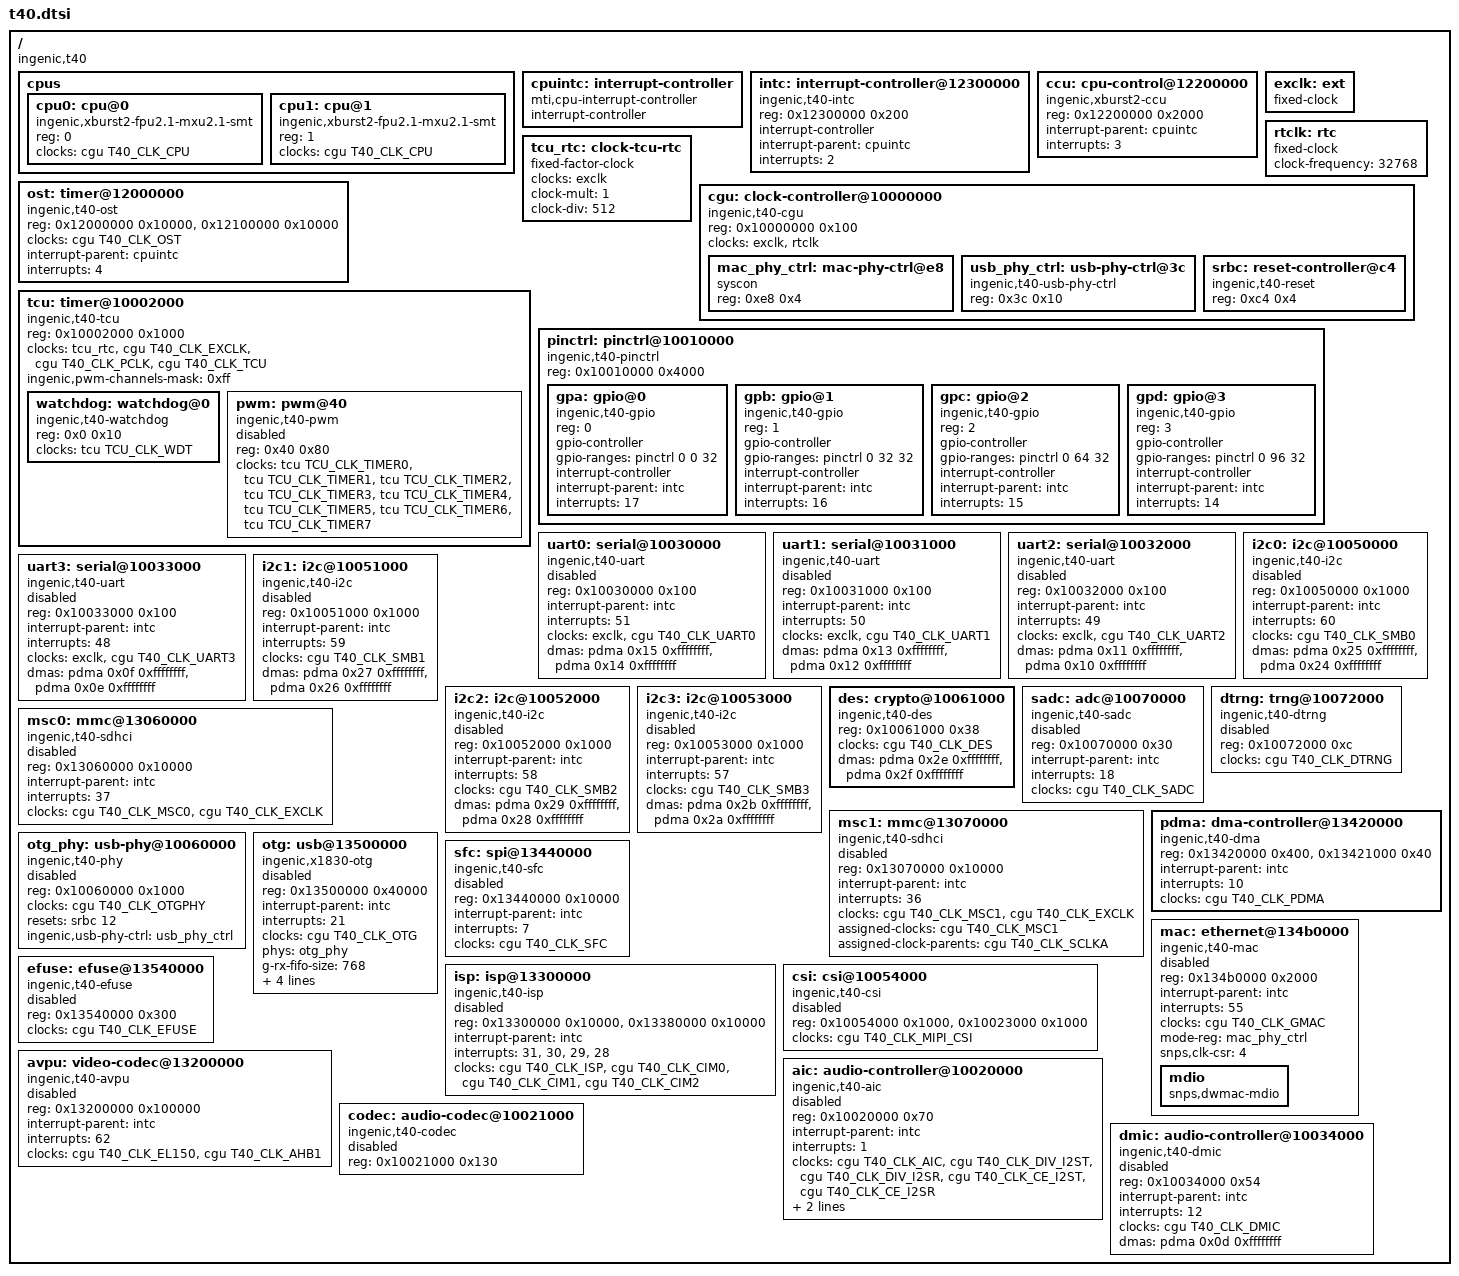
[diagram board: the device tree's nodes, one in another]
// SPDX-License-Identifier: GPL-2.0
#include <dt-bindings/clock/ingenic,t40-cgu.h>
#include <dt-bindings/clock/ingenic,tcu.h>

/ {
	#address-cells = <1>;
	#size-cells = <1>;
	compatible = "ingenic,t40";

	cpus {
		#address-cells = <1>;
		#size-cells = <0>;

		cpu0: cpu@0 {
			device_type = "cpu";
			compatible = "ingenic,xburst2-fpu2.1-mxu2.1-smt";
			reg = <0>;

			clocks = <&cgu T40_CLK_CPU>;
		};

		cpu1: cpu@1 {
			device_type = "cpu";
			compatible = "ingenic,xburst2-fpu2.1-mxu2.1-smt";
			reg = <1>;

			clocks = <&cgu T40_CLK_CPU>;
		};
	};

	cpuintc: interrupt-controller {
		#address-cells = <0>;
		#interrupt-cells = <1>;
		interrupt-controller;
		compatible = "mti,cpu-interrupt-controller";
	};

	/* One 0x100 window per core */
	intc: interrupt-controller@12300000 {
		compatible = "ingenic,t40-intc", "ingenic,t41-intc";
		reg = <0x12300000 0x200>;

		interrupt-controller;
		#interrupt-cells = <1>;

		interrupt-parent = <&cpuintc>;
		interrupts = <2>;
	};

	ccu: cpu-control@12200000 {
		compatible = "ingenic,xburst2-ccu";
		reg = <0x12200000 0x2000>;

		interrupt-parent = <&cpuintc>;
		interrupts = <3>;
	};

	exclk: ext {
		compatible = "fixed-clock";
		#clock-cells = <0>;
	};

	rtclk: rtc {
		compatible = "fixed-clock";
		#clock-cells = <0>;
		clock-frequency = <32768>;
	};

	/* RTC_EN of the TCU clocks EXCLK / 512, not the 32 kHz */
	tcu_rtc: clock-tcu-rtc {
		compatible = "fixed-factor-clock";
		clocks = <&exclk>;
		clock-mult = <1>;
		clock-div = <512>;
		#clock-cells = <0>;
	};

	cgu: clock-controller@10000000 {
		compatible = "ingenic,t40-cgu", "simple-mfd";
		reg = <0x10000000 0x100>;
		#address-cells = <1>;
		#size-cells = <1>;
		ranges = <0x0 0x10000000 0x100>;

		#clock-cells = <1>;

		clocks = <&exclk>, <&rtclk>;
		clock-names = "ext", "rtc";

		mac_phy_ctrl: mac-phy-ctrl@e8 {
			compatible = "syscon";
			reg = <0xe8 0x4>;
		};

		usb_phy_ctrl: usb-phy-ctrl@3c {
			compatible = "ingenic,t40-usb-phy-ctrl", "syscon";
			reg = <0x3c 0x10>;
		};

		srbc: reset-controller@c4 {
			compatible = "ingenic,t40-reset", "ingenic,t21-reset";
			reg = <0xc4 0x4>;
			#reset-cells = <1>;
		};
	};

	ost: timer@12000000 {
		compatible = "ingenic,t40-ost", "ingenic,t41-ost";
		reg = <0x12000000 0x10000>, <0x12100000 0x10000>;
		reg-names = "global", "core";

		clocks = <&cgu T40_CLK_OST>;
		clock-names = "ost";

		interrupt-parent = <&cpuintc>;
		interrupts = <4>;
	};

	tcu: timer@10002000 {
		compatible = "ingenic,t40-tcu", "ingenic,t32-tcu", "simple-mfd";
		reg = <0x10002000 0x1000>;
		#address-cells = <1>;
		#size-cells = <1>;
		ranges = <0x0 0x10002000 0x1000>;

		#clock-cells = <1>;

		clocks = <&tcu_rtc>,
			 <&cgu T40_CLK_EXCLK>,
			 <&cgu T40_CLK_PCLK>,
			 <&cgu T40_CLK_TCU>;
		clock-names = "rtc", "ext", "pclk", "tcu";

		/* the OST is the clocksource, so all eight channels are free */
		ingenic,pwm-channels-mask = <0xff>;

		watchdog: watchdog@0 {
			compatible = "ingenic,t40-watchdog", "ingenic,jz4780-watchdog";
			reg = <0x0 0x10>;

			clocks = <&tcu TCU_CLK_WDT>;
			clock-names = "wdt";
		};

		pwm: pwm@40 {
			compatible = "ingenic,t40-pwm", "ingenic,jz4740-pwm";
			reg = <0x40 0x80>;

			#pwm-cells = <3>;

			clocks = <&tcu TCU_CLK_TIMER0>,
				 <&tcu TCU_CLK_TIMER1>,
				 <&tcu TCU_CLK_TIMER2>,
				 <&tcu TCU_CLK_TIMER3>,
				 <&tcu TCU_CLK_TIMER4>,
				 <&tcu TCU_CLK_TIMER5>,
				 <&tcu TCU_CLK_TIMER6>,
				 <&tcu TCU_CLK_TIMER7>;
			clock-names = "timer0", "timer1", "timer2", "timer3",
				      "timer4", "timer5", "timer6", "timer7";

			status = "disabled";
		};
	};

	pinctrl: pinctrl@10010000 {
		compatible = "ingenic,t40-pinctrl";
		reg = <0x10010000 0x4000>;

		#address-cells = <1>;
		#size-cells = <0>;

		gpa: gpio@0 {
			compatible = "ingenic,t40-gpio";
			reg = <0>;

			gpio-controller;
			gpio-ranges = <&pinctrl 0 0 32>;
			#gpio-cells = <2>;

			interrupt-controller;
			#interrupt-cells = <2>;

			interrupt-parent = <&intc>;
			interrupts = <17>;
		};

		gpb: gpio@1 {
			compatible = "ingenic,t40-gpio";
			reg = <1>;

			gpio-controller;
			gpio-ranges = <&pinctrl 0 32 32>;
			#gpio-cells = <2>;

			interrupt-controller;
			#interrupt-cells = <2>;

			interrupt-parent = <&intc>;
			interrupts = <16>;
		};

		gpc: gpio@2 {
			compatible = "ingenic,t40-gpio";
			reg = <2>;

			gpio-controller;
			gpio-ranges = <&pinctrl 0 64 32>;
			#gpio-cells = <2>;

			interrupt-controller;
			#interrupt-cells = <2>;

			interrupt-parent = <&intc>;
			interrupts = <15>;
		};

		gpd: gpio@3 {
			compatible = "ingenic,t40-gpio";
			reg = <3>;

			gpio-controller;
			gpio-ranges = <&pinctrl 0 96 32>;
			#gpio-cells = <2>;

			interrupt-controller;
			#interrupt-cells = <2>;

			interrupt-parent = <&intc>;
			interrupts = <14>;
		};
	};

	uart0: serial@10030000 {
		compatible = "ingenic,t40-uart", "ingenic,x1000-uart";
		reg = <0x10030000 0x100>;

		interrupt-parent = <&intc>;
		interrupts = <51>;

		clocks = <&exclk>, <&cgu T40_CLK_UART0>;
		clock-names = "baud", "module";

		dmas = <&pdma 0x15 0xffffffff>, <&pdma 0x14 0xffffffff>;
		dma-names = "rx", "tx";

		status = "disabled";
	};

	uart1: serial@10031000 {
		compatible = "ingenic,t40-uart", "ingenic,x1000-uart";
		reg = <0x10031000 0x100>;

		interrupt-parent = <&intc>;
		interrupts = <50>;

		clocks = <&exclk>, <&cgu T40_CLK_UART1>;
		clock-names = "baud", "module";

		dmas = <&pdma 0x13 0xffffffff>, <&pdma 0x12 0xffffffff>;
		dma-names = "rx", "tx";

		status = "disabled";
	};

	uart2: serial@10032000 {
		compatible = "ingenic,t40-uart", "ingenic,x1000-uart";
		reg = <0x10032000 0x100>;

		interrupt-parent = <&intc>;
		interrupts = <49>;

		clocks = <&exclk>, <&cgu T40_CLK_UART2>;
		clock-names = "baud", "module";

		dmas = <&pdma 0x11 0xffffffff>, <&pdma 0x10 0xffffffff>;
		dma-names = "rx", "tx";

		status = "disabled";
	};

	uart3: serial@10033000 {
		compatible = "ingenic,t40-uart", "ingenic,x1000-uart";
		reg = <0x10033000 0x100>;

		interrupt-parent = <&intc>;
		interrupts = <48>;

		clocks = <&exclk>, <&cgu T40_CLK_UART3>;
		clock-names = "baud", "module";

		dmas = <&pdma 0x0f 0xffffffff>, <&pdma 0x0e 0xffffffff>;
		dma-names = "rx", "tx";

		status = "disabled";
	};

	i2c0: i2c@10050000 {
		compatible = "ingenic,t40-i2c", "ingenic,x1000-i2c";
		reg = <0x10050000 0x1000>;

		interrupt-parent = <&intc>;
		interrupts = <60>;

		clocks = <&cgu T40_CLK_SMB0>;

		dmas = <&pdma 0x25 0xffffffff>, <&pdma 0x24 0xffffffff>;
		dma-names = "rx", "tx";

		#address-cells = <1>;
		#size-cells = <0>;

		status = "disabled";
	};

	i2c1: i2c@10051000 {
		compatible = "ingenic,t40-i2c", "ingenic,x1000-i2c";
		reg = <0x10051000 0x1000>;

		interrupt-parent = <&intc>;
		interrupts = <59>;

		clocks = <&cgu T40_CLK_SMB1>;

		dmas = <&pdma 0x27 0xffffffff>, <&pdma 0x26 0xffffffff>;
		dma-names = "rx", "tx";

		#address-cells = <1>;
		#size-cells = <0>;

		status = "disabled";
	};

	i2c2: i2c@10052000 {
		compatible = "ingenic,t40-i2c", "ingenic,x1000-i2c";
		reg = <0x10052000 0x1000>;

		interrupt-parent = <&intc>;
		interrupts = <58>;

		clocks = <&cgu T40_CLK_SMB2>;

		dmas = <&pdma 0x29 0xffffffff>, <&pdma 0x28 0xffffffff>;
		dma-names = "rx", "tx";

		#address-cells = <1>;
		#size-cells = <0>;

		status = "disabled";
	};

	i2c3: i2c@10053000 {
		compatible = "ingenic,t40-i2c", "ingenic,x1000-i2c";
		reg = <0x10053000 0x1000>;

		interrupt-parent = <&intc>;
		interrupts = <57>;

		clocks = <&cgu T40_CLK_SMB3>;

		dmas = <&pdma 0x2b 0xffffffff>, <&pdma 0x2a 0xffffffff>;
		dma-names = "rx", "tx";

		#address-cells = <1>;
		#size-cells = <0>;

		status = "disabled";
	};

	des: crypto@10061000 {
		compatible = "ingenic,t40-des";
		reg = <0x10061000 0x38>;

		clocks = <&cgu T40_CLK_DES>;

		dmas = <&pdma 0x2e 0xffffffff>, <&pdma 0x2f 0xffffffff>;
		dma-names = "tx", "rx";
	};

	sadc: adc@10070000 {
		compatible = "ingenic,t40-sadc";
		reg = <0x10070000 0x30>;

		interrupt-parent = <&intc>;
		interrupts = <18>;

		clocks = <&cgu T40_CLK_SADC>;
		clock-names = "adc";

		#io-channel-cells = <1>;

		status = "disabled";
	};

	dtrng: trng@10072000 {
		compatible = "ingenic,t40-dtrng", "ingenic,x1830-dtrng";
		reg = <0x10072000 0xc>;

		clocks = <&cgu T40_CLK_DTRNG>;

		status = "disabled";
	};

	msc0: mmc@13060000 {
		compatible = "ingenic,t40-sdhci", "ingenic,t32-sdhci";
		reg = <0x13060000 0x10000>;

		interrupt-parent = <&intc>;
		interrupts = <37>;

		clocks = <&cgu T40_CLK_MSC0>, <&cgu T40_CLK_EXCLK>;
		clock-names = "mmc", "ext";

		status = "disabled";
	};

	msc1: mmc@13070000 {
		compatible = "ingenic,t40-sdhci", "ingenic,t32-sdhci";
		reg = <0x13070000 0x10000>;

		interrupt-parent = <&intc>;
		interrupts = <36>;

		clocks = <&cgu T40_CLK_MSC1>, <&cgu T40_CLK_EXCLK>;
		clock-names = "mmc", "ext";

		/*
		 * The boot loader leaves MSC1 alone and its mux can read EXCLK,
		 * which is not one of its sources here, so the clock would be
		 * an orphan: take the APLL, the source the vendor kernel's MSC
		 * dividers read.
		 */
		assigned-clocks = <&cgu T40_CLK_MSC1>;
		assigned-clock-parents = <&cgu T40_CLK_SCLKA>;

		status = "disabled";
	};

	pdma: dma-controller@13420000 {
		compatible = "ingenic,t40-dma", "ingenic,x1830-dma";
		reg = <0x13420000 0x400>, <0x13421000 0x40>;

		interrupt-parent = <&intc>;
		interrupts = <10>;

		clocks = <&cgu T40_CLK_PDMA>;

		#dma-cells = <2>;
	};

	otg_phy: usb-phy@10060000 {
		compatible = "ingenic,t40-phy", "ingenic,t32-phy";
		reg = <0x10060000 0x1000>;

		clocks = <&cgu T40_CLK_OTGPHY>;
		resets = <&srbc 12>;
		ingenic,usb-phy-ctrl = <&usb_phy_ctrl>;

		#phy-cells = <0>;

		status = "disabled";
	};

	otg: usb@13500000 {
		compatible = "ingenic,x1830-otg";
		reg = <0x13500000 0x40000>;

		interrupt-parent = <&intc>;
		interrupts = <21>;

		clocks = <&cgu T40_CLK_OTG>;
		clock-names = "otg";

		phys = <&otg_phy>;
		phy-names = "usb2-phy";

		/*
		 * The vendor kernel's split of the 3576 word FIFO RAM; the
		 * driver's default receive and non-periodic FIFOs leave the
		 * eight IN endpoints less than a high-speed bulk packet each
		 */
		g-rx-fifo-size = <768>;
		g-np-tx-fifo-size = <256>;
		g-tx-fifo-size = <256 256 256 256 256 256 256 512>;

		dr_mode = "host";

		status = "disabled";
	};

	sfc: spi@13440000 {
		compatible = "ingenic,t40-sfc", "ingenic,t32-sfc";
		reg = <0x13440000 0x10000>;

		interrupt-parent = <&intc>;
		interrupts = <7>;

		clocks = <&cgu T40_CLK_SFC>;
		clock-names = "sfc";

		#address-cells = <1>;
		#size-cells = <0>;

		status = "disabled";
	};

	mac: ethernet@134b0000 {
		compatible = "ingenic,t40-mac", "snps,dwmac";
		reg = <0x134b0000 0x2000>;

		interrupt-parent = <&intc>;
		interrupts = <55>;
		interrupt-names = "macirq";

		clocks = <&cgu T40_CLK_GMAC>;
		clock-names = "stmmaceth";

		mode-reg = <&mac_phy_ctrl>;

		snps,clk-csr = <4>;

		status = "disabled";

		mdio: mdio {
			compatible = "snps,dwmac-mdio";
			#address-cells = <1>;
			#size-cells = <0>;
		};
	};

	efuse: efuse@13540000 {
		compatible = "ingenic,t40-efuse";
		reg = <0x13540000 0x300>;

		clocks = <&cgu T40_CLK_EFUSE>;

		status = "disabled";
	};

	isp: isp@13300000 {
		compatible = "ingenic,t40-isp";
		reg = <0x13300000 0x10000>, <0x13380000 0x10000>;
		reg-names = "isp", "vic";

		interrupt-parent = <&intc>;
		interrupts = <31>, <30>, <29>, <28>;
		interrupt-names = "isp", "vic", "vic1", "vic2";

		clocks = <&cgu T40_CLK_ISP>, <&cgu T40_CLK_CIM0>,
			 <&cgu T40_CLK_CIM1>, <&cgu T40_CLK_CIM2>;
		clock-names = "isp", "cim0", "cim1", "cim2";

		status = "disabled";
	};

	csi: csi@10054000 {
		compatible = "ingenic,t40-csi";
		reg = <0x10054000 0x1000>, <0x10023000 0x1000>;
		reg-names = "csi", "csi2";

		clocks = <&cgu T40_CLK_MIPI_CSI>;
		clock-names = "csi";

		status = "disabled";
	};

	avpu: video-codec@13200000 {
		compatible = "ingenic,t40-avpu";
		reg = <0x13200000 0x100000>;

		interrupt-parent = <&intc>;
		interrupts = <62>;

		clocks = <&cgu T40_CLK_EL150>, <&cgu T40_CLK_AHB1>;
		clock-names = "avpu", "ahb1";

		status = "disabled";
	};

	aic: audio-controller@10020000 {
		compatible = "ingenic,t40-aic";
		reg = <0x10020000 0x70>;

		interrupt-parent = <&intc>;
		interrupts = <1>;

		clocks = <&cgu T40_CLK_AIC>,
			 <&cgu T40_CLK_DIV_I2ST>,
			 <&cgu T40_CLK_DIV_I2SR>,
			 <&cgu T40_CLK_CE_I2ST>,
			 <&cgu T40_CLK_CE_I2SR>;
		clock-names = "gate_aic", "div_i2st", "div_i2sr",
			      "ce_i2st", "ce_i2sr";

		dmas = <&pdma 0x07 0xffffffff>,
		       <&pdma 0x06 0xffffffff>,
		       <&pdma 0x05 0xffffffff>;
		dma-names = "rx", "tx", "aec";

		status = "disabled";
	};

	codec: audio-codec@10021000 {
		compatible = "ingenic,t40-codec";
		reg = <0x10021000 0x130>;

		status = "disabled";
	};

	dmic: audio-controller@10034000 {
		compatible = "ingenic,t40-dmic";
		reg = <0x10034000 0x54>;

		interrupt-parent = <&intc>;
		interrupts = <12>;

		clocks = <&cgu T40_CLK_DMIC>;
		clock-names = "gate_dmic";

		dmas = <&pdma 0x0d 0xffffffff>;
		dma-names = "rx";

		status = "disabled";
	};
};
